# DPHY_TX_DPHY_TX_301C0000h register map
Vendor: Texas Instruments
Peripheral module from a debugger description file (folder am62L).
Registers are 32-bit, read-write, reset 0x0 unless marked. A register's access mark holds for its fields unless they carry their own. Offsets are as the file gives them; lines under a group give offsets from that group; [hi:lo] are bit positions; {n}, {i} and the like mark numbered series; 'fields as' and 'values as' point back to an identical list; <NAME> marks a mode.

## DPHY_TX
0x00 DPHY_TX_DPHYTX access not given reset not defined
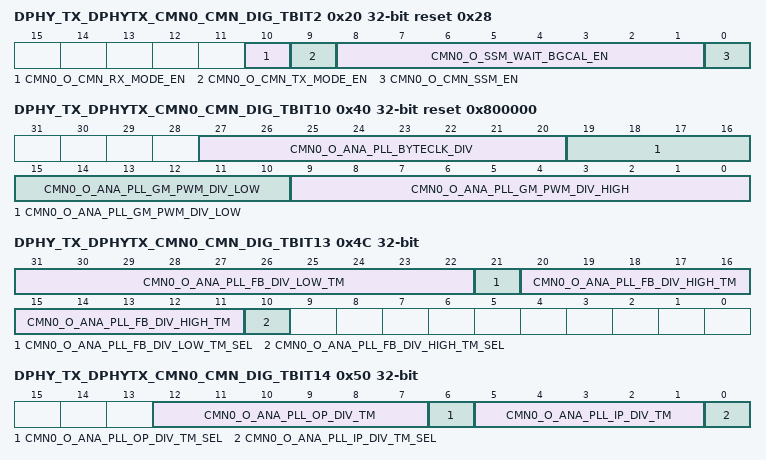
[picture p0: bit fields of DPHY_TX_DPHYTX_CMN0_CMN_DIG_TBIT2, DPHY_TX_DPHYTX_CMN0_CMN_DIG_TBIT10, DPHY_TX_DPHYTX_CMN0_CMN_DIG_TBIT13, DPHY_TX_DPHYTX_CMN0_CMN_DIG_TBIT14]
0x20 DPHY_TX_DPHYTX_CMN0_CMN_DIG_TBIT2 reset 0x28 — CMN_DIG_TBIT2
  [10] CMN0_O_CMN_RX_MODE_EN — Enable CMN RX related StateMachines
  [9] CMN0_O_CMN_TX_MODE_EN — Enable CMN TX related StateMachines
  [8:1] CMN0_O_SSM_WAIT_BGCAL_EN — Wait time for Calibrations enable after bandgap is enabled (in us)
  [0] CMN0_O_CMN_SSM_EN — Enable CMN startup state machine
0x40 DPHY_TX_DPHYTX_CMN0_CMN_DIG_TBIT10 reset 0x800000 — CMN_DIG_TBIT10
  [27:20] CMN0_O_ANA_PLL_BYTECLK_DIV — Byteclk divider value
  [19:10] CMN0_O_ANA_PLL_GM_PWM_DIV_LOW — Low division value setting for the gm PWM control divider
  [9:0] CMN0_O_ANA_PLL_GM_PWM_DIV_HIGH — High division value setting for the gm PWM control divider
0x4C DPHY_TX_DPHYTX_CMN0_CMN_DIG_TBIT13 — CMN_DIG_TBIT13
  [31:22] CMN0_O_ANA_PLL_FB_DIV_LOW_TM — forced value for pll_fb_div_clk_low
  [21] CMN0_O_ANA_PLL_FB_DIV_LOW_TM_SEL — pll_fb_div_clk_low forced from test registers
  [20:11] CMN0_O_ANA_PLL_FB_DIV_HIGH_TM — forced value for pll_fb_div_clk_high
  [10] CMN0_O_ANA_PLL_FB_DIV_HIGH_TM_SEL — pll_fb_div_clk_high forced from test registers
0x50 DPHY_TX_DPHYTX_CMN0_CMN_DIG_TBIT14 — CMN_DIG_TBIT14
  [12:7] CMN0_O_ANA_PLL_OP_DIV_TM — forced value for op_div
  [6] CMN0_O_ANA_PLL_OP_DIV_TM_SEL — op_div forced from test registers
  [5:1] CMN0_O_ANA_PLL_IP_DIV_TM — forced value for ip_div
  [0] CMN0_O_ANA_PLL_IP_DIV_TM_SEL — ip_div forced from test registers
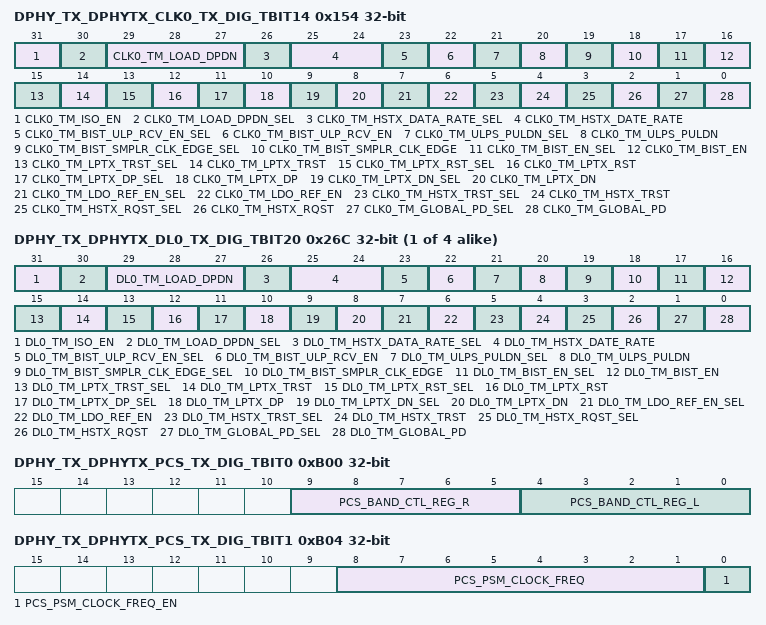
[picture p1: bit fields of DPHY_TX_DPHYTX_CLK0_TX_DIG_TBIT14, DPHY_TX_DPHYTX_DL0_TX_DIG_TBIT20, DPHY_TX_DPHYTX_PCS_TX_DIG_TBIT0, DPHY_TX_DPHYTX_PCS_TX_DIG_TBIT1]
0x154 DPHY_TX_DPHYTX_CLK0_TX_DIG_TBIT14 — digital to analog signals test muxing
  [31] CLK0_TM_ISO_EN — Enable isolation in test mode
  [30] CLK0_TM_LOAD_DPDN_SEL — Take ana_dpdn_load from dig logic
  [29:27] CLK0_TM_LOAD_DPDN — set ana_dpdn_load as per requirement in test mode
  [26] CLK0_TM_HSTX_DATA_RATE_SEL — Take ana_hstx_datarate from dig logic
  [25:24] CLK0_TM_HSTX_DATE_RATE — set ana_hstx_datarate as per requirement in test mode
  [23] CLK0_TM_BIST_ULP_RCV_EN_SEL — Take ana_bist_ulps_rcv_en from dig logic
  [22] CLK0_TM_BIST_ULP_RCV_EN — set ana_bist_ulps_rcv_en to 0
  [21] CLK0_TM_ULPS_PULDN_SEL — Take ana_ulps_puldn from dig logic
  [20] CLK0_TM_ULPS_PULDN — set ana_ulps_puldn to 0
  [19] CLK0_TM_BIST_SMPLR_CLK_EDGE_SEL — Take ana_bist_smplr_clkedge from dig logic
  [18] CLK0_TM_BIST_SMPLR_CLK_EDGE — set ana_bist_smplr_clkedge to posedge
  [17] CLK0_TM_BIST_EN_SEL — Take ana_bist_en from dig logic
  [16] CLK0_TM_BIST_EN — set ana_bist_en to 0
  [15] CLK0_TM_LPTX_TRST_SEL — Take ana_lptx_trst from dig logic
  [14] CLK0_TM_LPTX_TRST — set ana_lptx_trst to 0
  [13] CLK0_TM_LPTX_RST_SEL — Take ana_lptx_rst from dig logic
  [12] CLK0_TM_LPTX_RST — set ana_lptx_rst to 0
  [11] CLK0_TM_LPTX_DP_SEL — give output for LPTX DP from dig logic
  [10] CLK0_TM_LPTX_DP — send 0 to LP TX Dp
  [9] CLK0_TM_LPTX_DN_SEL — give output for LPTX DN from dig logic
  [8] CLK0_TM_LPTX_DN — send 0 to LP TX Dn
  [7] CLK0_TM_LDO_REF_EN_SEL — Take ana_ldo_ref_en from dig logic
  [6] CLK0_TM_LDO_REF_EN — set ana_ldo_ref_en to 0
  [5] CLK0_TM_HSTX_TRST_SEL — Take ana_hstx_trst from dig logic
  [4] CLK0_TM_HSTX_TRST — set ana_hstx_trst to 0
  [3] CLK0_TM_HSTX_RQST_SEL — Take ana_hstx_rqst from dig logic
  [2] CLK0_TM_HSTX_RQST — set ana_hstx_rqst to 0
  [1] CLK0_TM_GLOBAL_PD_SEL — Take ana_global_pd from dig logic
  [0] CLK0_TM_GLOBAL_PD — set ana_global_pd to 0 (powered up)
{0x26C+0x100*i} DPHY_TX_DPHYTX_DL{i}_TX_DIG_TBIT20 (i=0..3) — digital to analog signal muxing
  [31] DL{i}_TM_ISO_EN — Enable isolation in test mode
  [30] DL{i}_TM_LOAD_DPDN_SEL — Take ana_dpdn_load from dig logic
  [29:27] DL{i}_TM_LOAD_DPDN — set ana_dpdn_load as per requirement in test mode
  [26] DL{i}_TM_HSTX_DATA_RATE_SEL — Take ana_hstx_datarate from dig logic
  [25:24] DL{i}_TM_HSTX_DATE_RATE — set ana_hstx_datarate as per requirement in test mode
  [23] DL{i}_TM_BIST_ULP_RCV_EN_SEL — Take ana_bist_ulps_rcv_en from dig logic
  [22] DL{i}_TM_BIST_ULP_RCV_EN — set ana_bist_ulps_rcv_en to 0
  [21] DL{i}_TM_ULPS_PULDN_SEL — Take ana_ulps_puldn from dig logic
  [20] DL{i}_TM_ULPS_PULDN — set ana_ulps_puldn to 0
  [19] DL{i}_TM_BIST_SMPLR_CLK_EDGE_SEL — Take ana_bist_smplr_clkedge from dig logic
  [18] DL{i}_TM_BIST_SMPLR_CLK_EDGE — set ana_bist_smplr_clkedge to posedge
  [17] DL{i}_TM_BIST_EN_SEL — Take ana_bist_en from dig logic
  [16] DL{i}_TM_BIST_EN — set ana_bist_en to 0
  [15] DL{i}_TM_LPTX_TRST_SEL — Take ana_lptx_trst from dig logic
  [14] DL{i}_TM_LPTX_TRST — set ana_lptx_trst to 0
  [13] DL{i}_TM_LPTX_RST_SEL — Take ana_lptx_rst from dig logic
  [12] DL{i}_TM_LPTX_RST — set ana_lptx_rst to 0
  [11] DL{i}_TM_LPTX_DP_SEL — give output for LPTX DP from dig logic
  [10] DL{i}_TM_LPTX_DP — send 0 to LP TX Dp
  [9] DL{i}_TM_LPTX_DN_SEL — give output for LPTX DN from dig logic
  [8] DL{i}_TM_LPTX_DN — send 0 to LP TX Dn
  [7] DL{i}_TM_LDO_REF_EN_SEL — Take ana_ldo_ref_en from dig logic
  [6] DL{i}_TM_LDO_REF_EN — set ana_ldo_ref_en to 0
  [5] DL{i}_TM_HSTX_TRST_SEL — Take ana_hstx_trst from dig logic
  [4] DL{i}_TM_HSTX_TRST — set ana_hstx_trst to 0
  [3] DL{i}_TM_HSTX_RQST_SEL — Take ana_hstx_rqst from dig logic
  [2] DL{i}_TM_HSTX_RQST — set ana_hstx_rqst to 0
  [1] DL{i}_TM_GLOBAL_PD_SEL — Take ana_global_pd from dig logic
  [0] DL{i}_TM_GLOBAL_PD — set ana_global_pd to 0 (powered up)
0xB00 DPHY_TX_DPHYTX_PCS_TX_DIG_TBIT0 — PHY_BAND_CONTROL
  [9:5] PCS_BAND_CTL_REG_R — Data Rate [80_100] MHz
  [4:0] PCS_BAND_CTL_REG_L — Data Rate [80_100] MHz
0xB04 DPHY_TX_DPHYTX_PCS_TX_DIG_TBIT1 — PHY_PSM_CONFIG
  [8:1] PCS_PSM_CLOCK_FREQ — psm_clock freq value
  [0] PCS_PSM_CLOCK_FREQ_EN — take psm_clock_freq from tbit
0xF00 DPHY_TX_WIZ_CONFIG access not given reset not defined
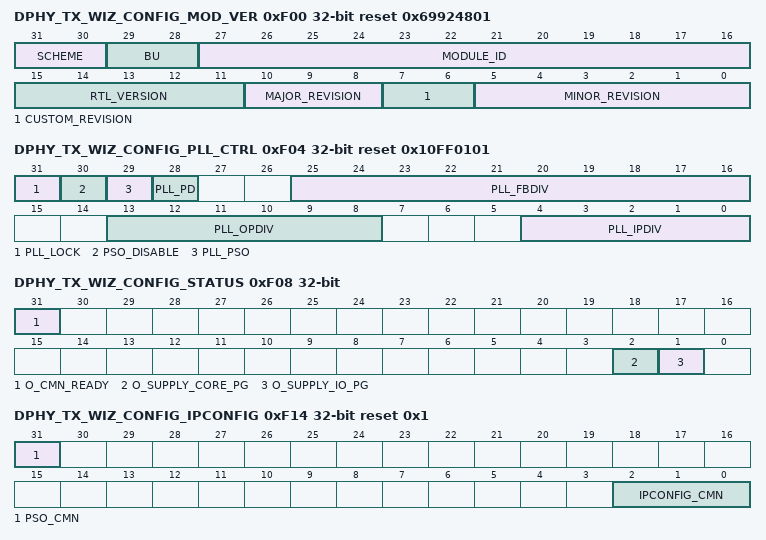
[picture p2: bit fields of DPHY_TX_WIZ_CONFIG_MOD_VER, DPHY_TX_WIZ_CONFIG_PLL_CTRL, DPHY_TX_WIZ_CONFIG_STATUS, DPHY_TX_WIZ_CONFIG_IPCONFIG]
0xF00 DPHY_TX_WIZ_CONFIG_MOD_VER ro reset 0x69924801 — The Module and Version Register identifies the module identifier and revision of the WIZ16B8M4CDT3 module.
  [31:30] SCHEME — Module Scheme
  [29:28] BU — Module Business Unit
  [27:16] MODULE_ID — WIZ16B8M4CDT3 module ID.
  [15:11] RTL_VERSION
  [10:8] MAJOR_REVISION
  [7:6] CUSTOM_REVISION
  [5:0] MINOR_REVISION
0xF04 DPHY_TX_WIZ_CONFIG_PLL_CTRL access per field reset 0x10FF0101 — Sets the PLL info.
  [31] PLL_LOCK ro — Signal to indicate that PLL has got locked. 1: PLL locked to required frequency 0: PLL not yet locked
  [30] PSO_DISABLE rw — Disables the ability to switch off the analog switched power islands in the lane when in the ultra-low power state
  [29] PLL_PSO rw — Power Shut Off signal for PLL 1: PLL shutoff 0: PLL power ON
  [28] PLL_PD rw — Power down signal for PLL (Does not switch off the PLL supply) 1: PLL is powered down 0: PLL is active
  [25:16] PLL_FBDIV rw — DPHY TX PLL VCO Feedback Divider ratio. Feedback divider value = ROUND ((Data Rate * 2 * pll_opdiv * pll_ipdiv) / PLL reference clock frequency)
  [13:8] PLL_OPDIV rw — DPHY TX PLL OUTCLK Divider ratio.<BR> 6'h01: Div by 1, 2.5 Gbps - 1.25 Gbps<BR> 6'h02: Div by 2, 1.24 Gbps - 630 Mbps<BR> 6'h04: Div by 4, 620 Mbps - 320 Mbps<BR> 6'h08: Div by 8, 310 Mbps - 160 Mbps<BR> 6'h10: Div by 16, 150 Mbps - 80 Mbps
  [4:0] PLL_IPDIV rw — DPHY TX PLL REFCLK Input Divider ratio.<BR> 5'h01: Div by 1, 9.6 MHz - <19.2 MHz<BR> 5'h02: Div by 2, 19.2 MHz - <38.4 MHz<BR> 5'h04: Div by 4, 38.4 MHz - < 76.8 MHz<BR> 5'h08: Div by 8, 76.8 MHz - < 150 MHz
0xF08 DPHY_TX_WIZ_CONFIG_STATUS ro — The status register reports status of the DPHYTS sub module.
  [31] O_CMN_READY — System Should check this during Power up Initialisation
  [2] O_SUPPLY_CORE_PG — The indicates the core supply is good.
  [1] O_SUPPLY_IO_PG — The indicates the IO supply is good.
0xF0C DPHY_TX_WIZ_CONFIG_RST_CTRL — Sets the RST info.
  [31] LANE_RSTB_CMN — DPHY System Reset for Common Module - required to be released after APB register programming; See DPHY PMA specification for details of DPHY power up sequence
0xF10 DPHY_TX_WIZ_CONFIG_PSM_FREQ reset 0x1 — The PSM Frequency register configures the so that it knows hoe fast the PSM clock is.
  [7:0] PSM_CLOCK_FREQ — Static value based on System PSM clock frequency. The signal must be driven with a value such that the internal psm frequency of the divided psm clock is 1 MHz
0xF14 DPHY_TX_WIZ_CONFIG_IPCONFIG reset 0x1
  [31] PSO_CMN — Power Shutoff signal for CMN 1: CMN is power OFF 0: CMN is power ON
  [2:0] IPCONFIG_CMN — This signal decides which clock lane acts as master clock lane to all data lanes. Needed only for RXIP. Bit[2]: Reserved CASE {Bit[1],Bit[0]}: 00: Left RX clk lane provides clock to all left and right data lanes. 01: Left RX clk lane provides clock to all right data lanes, Right RX clk lane provides clock to all left data lanes. 10: Right RX clk lane provides clock to all right data lanes, Left RX clk lane provides clock to all left data lanes. 11: Right RX clk lane provides clock to all left and right data lanes.
0xFF8 DPHY_TX_WIZ_CONFIG_PLLRES — The PLL Reserved register is not being used currently
  [7:0] PLLREFSEL_CMN — PLL frequency range. This signal is not being used currently. Should be 8'd0
0xFFC DPHY_TX_WIZ_CONFIG_DIAG_TEST — The Diagnostic Test Register allows the system to validate the read and write of all data bits.
  [31:0] DIAG_REG — Diagnostic register.
